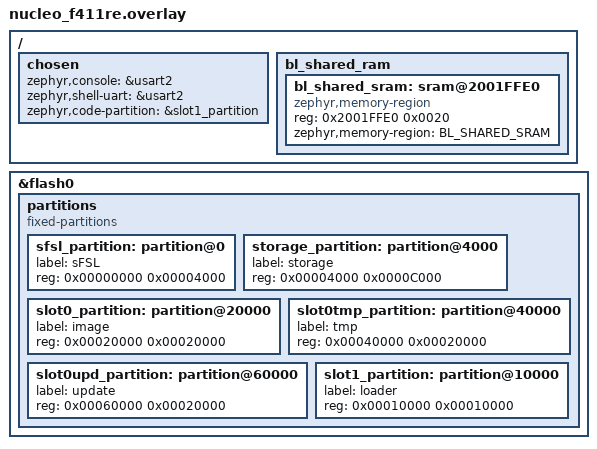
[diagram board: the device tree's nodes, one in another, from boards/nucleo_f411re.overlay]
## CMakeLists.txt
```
# SPDX-License-Identifier: Apache-2.0

cmake_minimum_required(VERSION 3.13.1)

# find_package(Zephyr) in order to load application boilerplate:
# http://docs.zephyrproject.org/application/application.html
find_package(Zephyr REQUIRED HINTS $ENV{ZEPHYR_BASE})

project(sSWPshell)

zephyr_include_directories(
    ${CMAKE_CURRENT_LIST_DIR}/include
)

FILE(GLOB app_sources src/main.c)

target_sources(app PRIVATE ${app_sources})
```

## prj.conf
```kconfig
CONFIG_SBK=y
CONFIG_SBK_MINCRYPT=y
CONFIG_FLASH=y
CONFIG_FLASH_SHELL=n
CONFIG_MAIN_STACK_SIZE=2048
CONFIG_SYSTEM_WORKQUEUE_STACK_SIZE=2048

CONFIG_SHELL=y
CONFIG_SHELL_MINIMAL=y
CONFIG_SHELL_STACK_SIZE=4096
CONFIG_SHELL_BACKEND_SERIAL=y
#CONFIG_SHELL_BACKEND_DUMMY=y
CONFIG_REBOOT=y
#CONFIG_PRINTK=y
#CONFIG_PICOLIBC=y

CONFIG_USE_DT_CODE_PARTITION=y
CONFIG_ROM_START_OFFSET=0x200
CONFIG_BOOT_BANNER=n
CONFIG_CONSOLE=y
CONFIG_LOG=y
CONFIG_SBK_LOG_LEVEL_DBG=y
CONFIG_LOG_MODE_MINIMAL=y
CONFIG_CBPRINTF_NANO=y
```

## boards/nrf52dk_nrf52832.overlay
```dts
/*
 * Copyright (c) 2022 Laczen
 *
 * SPDX-License-Identifier: Apache-2.0
 */

/delete-node/ &boot_partition;
/delete-node/ &slot0_partition;
/delete-node/ &slot1_partition;
/delete-node/ &storage_partition;

/ {
	chosen {
		zephyr,code-partition = &slot1_partition;
	};
};

&flash0 {
	partitions {
		compatible = "fixed-partitions";
		#address-cells = <1>;
		#size-cells = <1>;

		sfsl_partition: partition@0 {
			label = "sFSL";
			reg = <0x00000000 0x00002000>;
		};

		storage_partition: partition@2000 {
			label = "storage";
			reg = <0x00002000 0x00006000>;
		};

		slot0_partition: partition@8000 {
			label = "image";
			reg = <0x00008000 0x00028000>;
		};

		slot1_partition: partition@30000 {
			label = "loader";
			reg = <0x00030000 0x00010000>;
		};
	};
};

/ {
	bl_shared_ram {
		#address-cells = < 0x1 >;
		#size-cells = < 0x1 >;

		bl_shared_sram: sram@20000000 {
			compatible = "zephyr,memory-region", "mmio-sram";
			reg = < 0x20000000 0x0020 >;
			zephyr,memory-region = "BL_SHARED_SRAM";
		};
	};
};
```

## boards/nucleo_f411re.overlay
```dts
/*
 * Copyright (c) 2022 Laczen
 *
 * SPDX-License-Identifier: Apache-2.0
 */

/ {
	chosen {
		zephyr,console = &usart2;
		zephyr,shell-uart = &usart2;
		zephyr,code-partition = &slot1_partition;
	};
};

&flash0 {
	partitions {
		compatible = "fixed-partitions";
		#address-cells = <1>;
		#size-cells = <1>;

		sfsl_partition: partition@0 {
			label = "sFSL";
			reg = <0x00000000 0x00004000>;
		};

		storage_partition: partition@4000 {
			label = "storage";
			reg = <0x00004000 0x0000C000>;
		};

		slot0_partition: partition@20000 {
			label = "image";
			reg = <0x00020000 0x00020000>;
		};

		slot0tmp_partition: partition@40000 {
			label ="tmp";
			reg = <0x00040000 0x00020000>;
		};

		slot0upd_partition: partition@60000 {
			label ="update";
			reg = <0x00060000 0x00020000>;
		};

		slot1_partition: partition@10000 {
			label = "loader";
			reg = <0x00010000 0x00010000>;
		};
	};
};

/ {
	bl_shared_ram {
		#address-cells = < 0x1 >;
		#size-cells = < 0x1 >;

		bl_shared_sram: sram@2001FFE0 {
			compatible = "zephyr,memory-region", "mmio-sram";
			reg = < 0x2001FFE0 0x0020 >;
			zephyr,memory-region = "BL_SHARED_SRAM";
		};
	};
};
```

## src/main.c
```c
/*
 * Copyright (c) 2022 Laczen
 *
 * SPDX-License-Identifier: Apache-2.0
 */

#include <stdarg.h>
#include <string.h>
#include <stdio.h>
#include <stdlib.h>
#include <zephyr/kernel.h>
#include <zephyr/drivers/flash.h>
#include <zephyr/sys/reboot.h>
#include <zephyr/device.h>
#include <zephyr/devicetree.h>
#include <zephyr/linker/devicetree_regions.h>
#include <zephyr/shell/shell.h>
#include <zephyr/logging/log.h>

LOG_MODULE_REGISTER(sswpshell, LOG_LEVEL_DBG); 

#include "sbk/sbk_image.h"
#include "sbk/sbk_slot.h"
#include "sbk/sbk_util.h"
#include "sbk/sbk_product.h"

#define FLASH_OFFSET CONFIG_FLASH_BASE_ADDRESS
#define ERASE_BLOCK_SIZE 0x1000

#define SLOT0_NODE		DT_NODELABEL(slot0_partition)
#define SLOT0_MTD               DT_MTD_FROM_FIXED_PARTITION(SLOT0_NODE)
#define SLOT0_DEVICE	        DEVICE_DT_GET(SLOT0_MTD)
#define SLOT0_OFFSET	        DT_REG_ADDR(SLOT0_NODE)
#define SLOT0_SIZE              DT_REG_SIZE(SLOT0_NODE)
#define SLOT1_NODE		DT_NODELABEL(slot1_partition)
#define SLOT1_MTD               DT_MTD_FROM_FIXED_PARTITION(SLOT1_NODE)
#define SLOT1_DEVICE	        DEVICE_DT_GET(SLOT1_MTD)
#define SLOT1_OFFSET	        DT_REG_ADDR(SLOT1_NODE)
#define SLOT1_SIZE              DT_REG_SIZE(SLOT1_NODE)
#define SLOT0UPD_NODE		DT_NODELABEL(slot0upd_partition)
#define SLOT0UPD_MTD            DT_MTD_FROM_FIXED_PARTITION(SLOT0UPD_NODE)
#define SLOT0UPD_DEVICE	        DEVICE_DT_GET(SLOT0UPD_MTD)
#define SLOT0UPD_OFFSET	        DT_REG_ADDR(SLOT0UPD_NODE)
#define SLOT0UPD_SIZE           DT_REG_SIZE(SLOT0UPD_NODE)
#define SLOT0TMP_NODE		DT_NODELABEL(slot0tmp_partition)
#define SLOT0TMP_MTD            DT_MTD_FROM_FIXED_PARTITION(SLOT0TMP_NODE)
#define SLOT0TMP_DEVICE	        DEVICE_DT_GET(SLOT0TMP_MTD)
#define SLOT0TMP_OFFSET	        DT_REG_ADDR(SLOT0TMP_NODE)
#define SLOT0TMP_SIZE           DT_REG_SIZE(SLOT0TMP_NODE)

#define BL_SHARED_SRAM_NODE	DT_NODELABEL(bl_shared_sram)
#define BL_SHARED_SRAM_SECT	LINKER_DT_NODE_REGION_NAME(BL_SHARED_SRAM_NODE)
#define BL_SHARED_SRAM_ADDR	DT_REG_ADDR(BL_SHARED_SRAM_NODE)
#define BL_SHARED_SRAM_SIZE	DT_REG_SIZE(BL_SHARED_SRAM_NODE)

/**
 * @brief shared data format definition
 */

struct __attribute__((aligned (BL_SHARED_SRAM_SIZE))) sbk_shared_data {
        uint32_t product_hash;
        struct sbk_version product_ver;
        uint8_t bslot;
        uint8_t bcnt;
};

struct sbk_shared_data shared_data Z_GENERIC_SECTION(BL_SHARED_SRAM_SECT);

/**
 * @brief Loader slot setup
 * 
 */

struct flash_slot_ctx {
        const struct device *dev;
        uint32_t off;
        uint32_t size;
};

const struct flash_slot_ctx slots[4] = {
        {
                .dev = SLOT0_DEVICE,
                .off = SLOT0_OFFSET,
                .size = SLOT0_SIZE,
        },
        {
                .dev = SLOT0UPD_DEVICE,
                .off = SLOT0UPD_OFFSET,
                .size = SLOT0UPD_SIZE,
        },
        {
                .dev = SLOT0TMP_DEVICE,
                .off = SLOT0TMP_OFFSET,
                .size = SLOT0TMP_SIZE,
        },
        {
                .dev = SLOT1_DEVICE,
                .off = SLOT1_OFFSET,
                .size = SLOT1_SIZE,
        }
};

static int read(const void *ctx, unsigned long off, void *data, size_t len)
{
        const struct flash_slot_ctx *sctx = (const struct flash_slot_ctx *)ctx;

        return flash_read(sctx->dev, sctx->off + off, data, len);
}

static int address(const void *ctx, unsigned long off, unsigned long *address)
{
        const struct flash_slot_ctx *sctx = (const struct flash_slot_ctx *)ctx;

        *address = FLASH_OFFSET + sctx->off;
        return 0;
}

static int prog(const void *ctx, unsigned long off, const void *data, size_t len)
{
        const struct flash_slot_ctx *sctx = (const struct flash_slot_ctx *)ctx;
        int rc;

        if (((sctx->off + off) % ERASE_BLOCK_SIZE) == 0U) {
                LOG_DBG("Erasing flash at %lx", sctx->off + off);
                rc = flash_erase(sctx->dev, sctx->off + off, ERASE_BLOCK_SIZE);
                if (rc != 0) {
                        goto end;
                }
        }

        rc = flash_write(sctx->dev, sctx->off + off, data, len);
end:
        return rc;
}

static int slot_get(struct sbk_slot *slot, unsigned int slot_no)
{
        if (slot_no >= ARRAY_SIZE(slots)) {
                return -SBK_EC_ENOENT;
        }

        slot->ctx = (void *)&slots[slot_no];
        slot->size = slots[slot_no].size;
        slot->read = read;
        slot->prog = prog;
        slot->address = address;
        slot->open = NULL;
        slot->close = NULL;
        return 0;
}

int (*sbk_slot_get)(struct sbk_slot *slot, unsigned int slot_no) = slot_get;

/**
 * @brief Shell interface
 * 
 */
int cli_command_reboot(const struct shell *sh, int argc, char *argv[]) {
        shell_print(sh, "Rebooting");
        sys_reboot(0);
        return 0;
}

#define IMG_BUF_SIZE 512
static uint8_t img_buffer[IMG_BUF_SIZE];
static size_t ldsize;
static unsigned long ldoff;
static bool ldok;
static struct sbk_slot ldslot;

void cli_upload_block(const struct shell *sh, uint8_t *data, size_t len)
{
        int rc;

        if ((ldoff == 0) && (*data != 0xff)) {
                data++;
                len--; 
        }

        while (len != 0) {
                unsigned long boff = ldoff & (IMG_BUF_SIZE - 1);
                unsigned long wroff = ldoff & ~(IMG_BUF_SIZE - 1);
                size_t cplen = SBK_MIN(len, IMG_BUF_SIZE - boff);

                memcpy(img_buffer + boff, data, cplen);
                boff += cplen;
                len -= cplen;
                ldoff += cplen;
                ldsize -= cplen;
                data += cplen;

                if (((boff == IMG_BUF_SIZE) || (ldsize == 0U)) && (ldok)) {
                        rc = sbk_slot_prog(&ldslot, wroff, img_buffer, boff);
                        if (rc != 0) {
                                ldok = false;
                                shell_print(sh, "Write failed");
                        }
                }
        }

        if (((ldoff % 32) == 0U) || (ldsize == 0U)) {
                shell_print(sh, "off: %ld, rs: %d OK", ldoff, ldsize);
        }

        if (ldsize == 0U) {
                sbk_slot_close(&ldslot);
                shell_set_bypass(sh, NULL);
        }
}

void main(void);

static bool is_running(const struct sbk_slot *slt) {
        const unsigned long ma = (unsigned long)main;
        unsigned long saddr;
        
        if ((sbk_slot_address(slt, 0U, &saddr) != 0) ||
            (saddr > ma) || ((saddr + slt->size) <= ma)) {
                return false;
        }

        return true;
}

int cli_command_upload(const struct shell *sh, int argc, char *argv[]) {
        uint32_t slot;

        if (argc < 2) {
                shell_print(sh, "Insufficient arguments");
                return 0;
        }

        slot = strtoul(argv[1], NULL, 0);
        ldsize = strtoul(argv[2], NULL, 0);

        if ((sbk_slot_get(&ldslot, slot) != 0) || (slot == 0U)) {
                shell_print(sh, "Bad slot specified");
                return 0;
        }

        if (sbk_slot_open(&ldslot) != 0) {
                shell_print(sh, "Cannot open slot %d", slot);
                return 0;
        }

        if (ldslot.size < ldsize) {
                shell_print(sh, "Image to large");
                return 0;
        }

        if (is_running(&ldslot)) {
                shell_print(sh, "Cannot upgrade running image");
                return 0;
        }

        ldoff = 0U;
        ldok = true;
        shell_set_bypass(sh, cli_upload_block);
        shell_print(sh, "OK");
        return 0;
}

int cli_command_list(const struct shell *sh, int argc, char *argv[]) {
        uint32_t slot_no = 0;
        struct sbk_slot slot;
	
        while (true) {
                struct sbk_image_state st;
                int rc;
                
                rc = sbk_slot_get(&slot, slot_no);
                if (rc != 0) {
                        break;
                }

                rc = sbk_slot_open(&slot);
                if (rc != 0) {
                        break;
                }

                SBK_IMAGE_STATE_CLR_FLAGS(st.state_flags);
                rc = sbk_image_get_state_upd(&slot, &st);                
                (void)sbk_slot_close(&slot);
                
                if (rc != 0) {
                        shell_print(sh, "Slot %d: no valid image", slot_no);
                        slot_no++;
                        continue;
                }
                
                shell_print(sh, "Slot %d: version %d.%d-%d %s flags %x",
                            slot_no, st.image_version.major, 
                            st.image_version.minor, st.image_version.revision, 
                            is_running(&slot) ? "(running)" : "",
                            st.state_flags);
                slot_no++;
        }

	return 0;

}

int cli_command_copy(const struct shell *sh, int argc, char *argv[]) {
        uint32_t slot_no_src, slot_no_dst;
        struct sbk_slot slot_src, slot_dst;

        if (argc < 2) {
                shell_print(sh, "Insufficient arguments");
                return 0;
        }

        slot_no_src = strtoul(argv[1], NULL, 0);
        slot_no_dst = strtoul(argv[2], NULL, 0);

        if ((sbk_slot_get(&slot_src, slot_no_src) != 0) ||
            (sbk_slot_get(&slot_dst, slot_no_dst) != 0) ||
            (slot_no_src == 3) || (slot_no_dst == 3)) {
                shell_print(sh, "Bad slot specified");
                goto end;
        }

        if (sbk_slot_open(&slot_src) != 0) {
                shell_print(sh, "Cannot open slot %d", slot_no_src);
                goto end;
        }

        if (sbk_slot_open(&slot_dst) != 0) {
                shell_print(sh, "Cannot open slot %d", slot_no_dst);
                goto end_slot_src;
        }

        int rc = sbk_image_copy(&slot_dst, &slot_src);
        shell_print(sh, "Copying slot %d to %d [%s]", slot_no_src, slot_no_dst,
                    rc == 0 ? "Success" : "Failed");

        sbk_slot_close(&slot_dst);
end_slot_src:
        sbk_slot_close(&slot_src);
end:
        return 0;
}

int cli_command_swap(const struct shell *sh, int argc, char *argv[]) {
        uint32_t slot_no_src, slot_no_dst, slot_no_tmp;
        struct sbk_slot slot_src, slot_dst, slot_tmp;

        if (argc < 3) {
                shell_print(sh, "Insufficient arguments");
                return 0;
        }

        slot_no_dst = strtoul(argv[1], NULL, 0);
        slot_no_src = strtoul(argv[2], NULL, 0);
        slot_no_tmp = strtoul(argv[3], NULL, 0);

        if ((sbk_slot_get(&slot_src, slot_no_src) != 0) ||
            (sbk_slot_get(&slot_dst, slot_no_dst) != 0) ||
            (sbk_slot_get(&slot_tmp, slot_no_tmp) != 0) ||
            (slot_no_src == 3) || (slot_no_dst == 3) || (slot_no_tmp != 2)) {
                shell_print(sh, "Bad slot specified");
                goto end;
        }

        if (sbk_slot_open(&slot_src) != 0) {
                shell_print(sh, "Cannot open slot %d", slot_no_src);
                goto end;
        }

        if (sbk_slot_open(&slot_dst) != 0) {
                shell_print(sh, "Cannot open slot %d", slot_no_dst);
                goto end_slot_src;
        }

        if (sbk_slot_open(&slot_tmp) != 0) {
                shell_print(sh, "Cannot open slot %d", slot_no_tmp);
                goto end_slot_tmp;
        }

        int rc = sbk_image_swap(&slot_dst, &slot_src, &slot_tmp, 0x20000);
        shell_print(sh, "Swapping slot %d to %d [%s]", slot_no_src, slot_no_dst,
                    rc == 0 ? "Success" : "Failed");

end_slot_tmp:
        sbk_slot_close(&slot_dst);
end_slot_src:
        sbk_slot_close(&slot_src);
end:
        return 0;
}

SHELL_STATIC_SUBCMD_SET_CREATE(
        image,
        SHELL_CMD(upload, NULL, "Upload new firmware", cli_command_upload),
        SHELL_CMD(list, NULL, "List available images", cli_command_list),
        SHELL_CMD(copy, NULL, "Copy image", cli_command_copy),
        SHELL_CMD(swap, NULL, "Swap image", cli_command_swap),
        SHELL_CMD(reboot, NULL, "Reboot", cli_command_reboot),
        SHELL_SUBCMD_SET_END
);

SHELL_CMD_REGISTER(image, &image, "Working with images", NULL);

void main(void)
{          
        LOG_INF("Welcome to %x version %d.%d-%d", shared_data.product_hash,
                shared_data.product_ver.major, 
                shared_data.product_ver.minor,
                shared_data.product_ver.revision);
        LOG_INF("Running from slot %d", shared_data.bslot);
        LOG_INF("Boot retries %d", shared_data.bcnt);
        LOG_INF("Main located at: %p", main);
}
```
